# A34L71x register map
Vendor: ABOV Semiconductor Co., Ltd.; File version: 1.0
CPU: CM4 r0p1, little endian, MPU, FPU, VTOR, 4 interrupt priority bits
Registers are 32-bit, read-write, reset 0x0 unless marked. A register's access mark holds for its fields unless they carry their own. Offsets are from the block's base; [hi:lo] are bit positions; {n}, {i} and the like mark numbered series.

## PORTEN — General Port Access Enable
Base 0x41004FF0
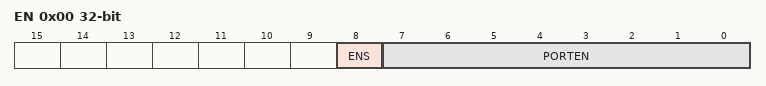
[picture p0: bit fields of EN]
0x00 EN wo — Port Access Enable Register
  [8] ENS ro — Pin Clear bit, x = 0 to 15
  [7:0] PORTEN — PCU and GPIO register access enable (0x15, 0x51)

## DFMC — DATA FLASH MEMORY CONTROLLER
Base 0x41001000
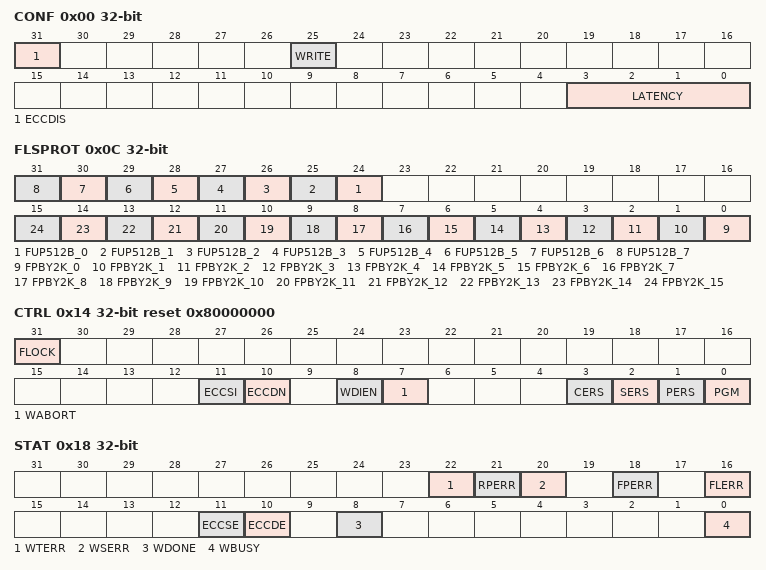
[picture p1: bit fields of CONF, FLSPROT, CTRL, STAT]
0x00 CONF — data flash control register
  [31] ECCDIS — Disable Data Flash ECC
    0=Disable (ECC enable); 1=Enable (ECC disable)
  [25] WRITE — Whether to Enable or Disable the Data Flash Write
    0=Disable write; 1=Enable write
  [3:0] LATENCY — Flash Wait Value Bits
0x04 FLSKEY — data flash access key register
  [31:0] FKEY — These bits are the key values used to access the flash memory, KEY1(0x01234567) -> KEY2(0x12345678) -> KEY3(0x23456789)
0x0C FLSPROT — data flash protection register
  [n+24] FUP512B_{n} (n=0..7) — Flash upper 512B Unprotection
  [n] FPBY2K_{n} (n=0..15) — Flash 2KB Protection
0x14 CTRL reset 0x80000000 — data flash access control register
  [31] FLOCK — data flash access control bit
  [11] ECCSI — Whether to enable or disable the ECC single error interrupt
  [10] ECCDN — Whether to enable or disable the ECC double error non-maskable interrupt
  [8] WDIEN — Write done interrupt enable
  [7] WABORT — Write abort settings
  [3] CERS — Flash memory bulk(chip) erase mode
  [2] SERS — Flash memory sector (2 KB) erase mode
  [1] PERS — Flash memory page (512 Bytes) erase mode
  [0] PGM — Program Mode
0x18 STAT — data flash access status register
  [22] WTERR — Write timeout error (cleared by writing a '1')
  [21] RPERR — Read-protect error (cleared by writing a '1')
  [20] WSERR — Write sequence error (cleared by writing a '1')
  [18] FPERR — Flash protect error (auto cleared)
  [16] FLERR — Flash lock error (auto cleared)
  [11] ECCSE — ECC single error
  [10] ECCDE — ECC double error
  [8] WDONE — Write done interrupt status (cleared by writing a '1')
  [0] WBUSY ro — Write Busy Check
    0=Not_Busy (Checksum Not Busy); 1=Busy (Checksum Busy)
0x40 WTIMEOUT — data flash write time-out register
  [31:0] WTIMEOUT — write time-out setting bit
0x50 ECCEADDR — Data Flash ECC Error Address Register
  [15:0] ECCEA ro — ECC error address (Offset: 0x0E00_0000)
0x54 ECCEDATA — Data Flash ECC Error Data Register
  [15:0] ECCED ro — ECC error data (Offset: 0x0E00_0000)
0x58 ECCEPARITY — Data Flash ECC Error Parity Register
  [6:0] ECCEP ro — ECC error parity

## DMA — Direct Memory Access Control 0
Base 0x50000400
Same registers: DMA0 0x40000400, DMA1 0x40000410, DMA2 0x40000420, DMA3 0x40000430, DMA4 0x40000440, DMA5 0x40000450, DMA6 0x40000460
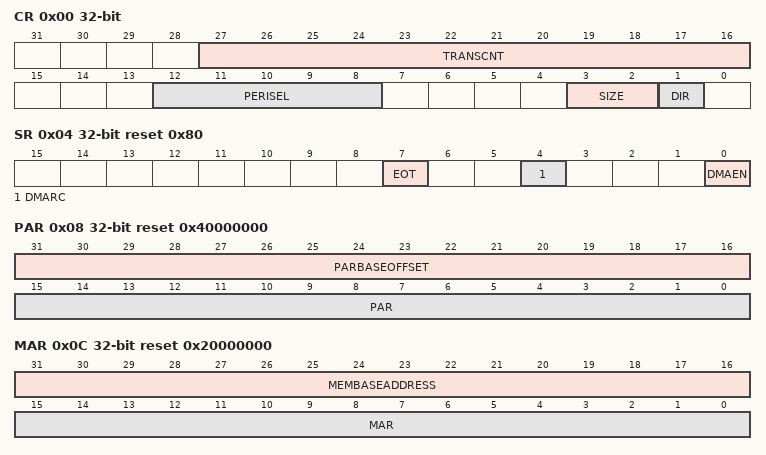
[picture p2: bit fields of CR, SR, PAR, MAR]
0x00 CR — DMA channel n control register
  [27:16] TRANSCNT — Number of DMA transfers Before enabling
  [12:8] PERISEL — Peripheral selection
  [3:2] SIZE — Bus transfer size
    0=Byte (transmit byte size); 1=half_word (transmit half word size); 2=word (transmit word size)
  [1] DIR — Transfer direction selection
    0=MEM-PERI (Memory->Peripheral); 1=PERI-MEM (Peripheral->Memory)
0x04 SR reset 0x80 — DMA channel n status register
  [7] EOT ro — Transfer ends
    0=BUSY (Transmit data is Busy); 1=EMPTY (Transmit complete)
  [4] DMARC — DMA request clear (Auto clear)
    1=Clear (DMA Clear)
  [0] DMAEN — Enables DMA use
0x08 PAR reset 0x40000000 — DMA channel n peripheral address register
  [31:16] PARBASEOFFSET ro — Peripheral base address offset
  [15:0] PAR — Address of the transfer / receive buffers target peripheral
0x0C MAR reset 0x20000000 — DMA channel n memory address register
  [31:16] MEMBASEADDRESS ro — Memory base address offset
  [15:0] MAR — Target memory address of the data transfer
